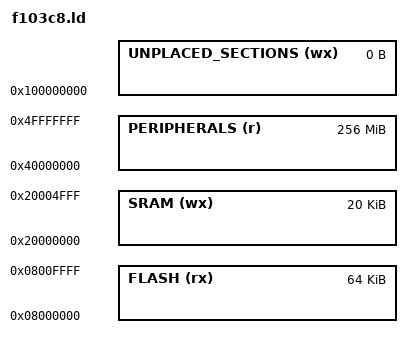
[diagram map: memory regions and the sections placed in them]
MEMORY{
  UNPLACED_SECTIONS (wx) : ORIGIN = 4096M, LENGTH = 0
  FLASH (rx) : ORIGIN = 128M, LENGTH = 64K
  SRAM (wx) :  ORIGIN = 512M, LENGTH = 20K
  PERIPHERALS (r): ORIGIN = 1024M, LENGTH = 256M
}

